# i3c_reva register map
Registers are 32-bit, read-write, no defined reset value unless marked. A register's access mark holds for its fields unless they carry their own. Offsets are from the block's base; lines under a group give offsets from that group; [hi:lo] are bit positions; {n}, {i} and the like mark numbered series; 'fields as' and 'values as' point back to an identical list; <NAME> marks a mode.

## Memory map
0x40018000 I3C0 size 0x1000 — Improved Inter-Integrated Circuit.

## Interrupts
30 I3C0 — I3C0 IRQ

## I3C0 — Improved Inter-Integrated Circuit.
Base 0x40018000
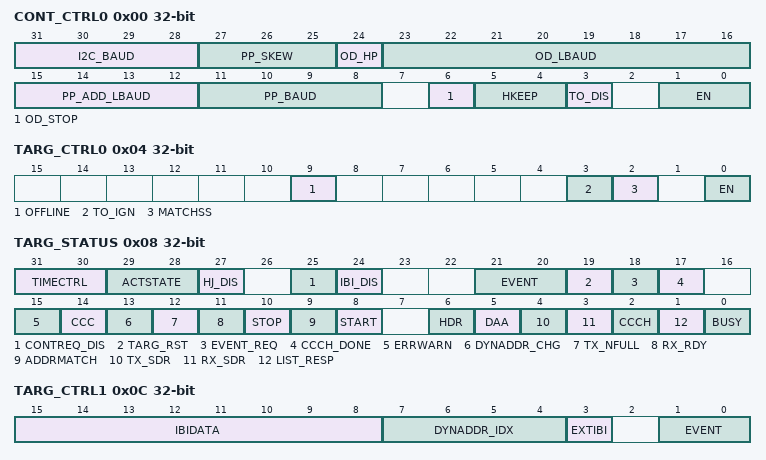
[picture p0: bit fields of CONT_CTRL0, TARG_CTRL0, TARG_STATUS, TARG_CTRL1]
0x00 CONT_CTRL0 — Controller Control 0 (Configuration) Register.
  [31:28] I2C_BAUD — Detyermines SCL high and low pweriods for I2C mode, in units of OD_BAUD period.
  [27:25] PP_SKEW — Number of FCLK periods to delay the SDA value change from the SCL edge for I3C push-pull operation.
  [24] OD_HP — Controls SCL high period for I3C oepn-drain operation.
  [23:16] OD_LBAUD — Number of PP_BAUD periods minus 1 to make one SCL low period for I3C open-dran periods.
  [15:12] PP_ADD_LBAUD — Number of FCLK periods to add to the base of SCL low period.
    0=0_FCLK (Adds zero FCLK periods to the SCL low period.); 1=1_FCLK (Adds one FCLK period to the SCL low period.); 2=2_FCLK (Adds two FCLK periods to the SCL low period.); 3=3_FCLK (Adds three FCLK periods to the SCL low period.); 4=4_FCLK (Adds four FCLK periods to the SCL low period.); 5=5_FCLK (Adds five FCLK periods to the SCL low period.); 6=6_FCLK (Adds six FCLK periods to the SCL low period.); 7=7_FCLK (Adds seven FCLK periods to the SCL low period.); 8=8_FCLK (Adds eight FCLK periods to the SCL low period.); 9=9_FCLK (Adds nine FCLK periods to the SCL low period.); 10=10_FCLK (Adds ten FCLK periods to the SCL low period.); 11=11_FCLK (Adds eleven FCLK periods to the SCL low period.); 12=12_FCLK (Adds twelve FCLK periods to the SCL low period.); 13=13_FCLK (Adds thirteen FCLK periods to the SCL low period.); 14=14_FCLK (Adds fourteen FCLK periods to the SCL low period.); 15=15_FCLK (Adds fifthteen FCLK periods to the SCL low period.)
  [11:8] PP_BAUD — SCL Frequency for push-pull drive.
    0=1_FCLK (SCL High Period is one FCLK Period.); 1=2_FCLK (SCL High Period is two FLCK Periods.); 2=3_FCLK (SCL High Period is three FCLK Period.); 3=4_FCLK (SCL High Period is four FCLK Period.); 4=5_FCLK (SCL High Period is five FCLK Period.); 5=6_FCLK (SCL High Period is six FCLK Period.); 6=7_FCLK (SCL High Period is seven FCLK Period.); 7=8_FCLK (SCL High Period is eight FCLK Period.); 8=9_FCLK (SCL High Period is nine FCLK Period.); 9=10_FCLK (SCL High Period is ten FCLK Period.); 10=11_FCLK (SCL High Period is eleven FCLK Period.); 11=12_FCLK (SCL High Period is twelve FCLK Period.); 12=13_FCLK (SCL High Period is thirteen FCLK Period.); 13=14_FCLK (SCL High Period is fourteen FCLK Period.); 14=15_FCLK (SCL High Period is fifthteen FCLK Period.); 15=16_FCLK (SCL High Period is sixteen FCLK Period.)
  [6] OD_STOP — Use open-drain speed for STOP.
  [5:4] HKEEP — High-keepr implementation.
    0=OFF (No high-keeper support.); 1=ON_CHIP (On-chip high-keeper support.); 2=EXT_SDA (External high-keeper support for SDA.); 3=EXT_SCL_SDA (External high-keeper support for SCL and SDA.)
  [3] TO_DIS — Disable Timeout error.
  [1:0] EN — I3C Device Enable.
    0=OFF; 1=ON; 2=CAP (I23 Bug Target with secondary controller capability.)
0x04 TARG_CTRL0 — Target Control 0 (Configuration) Register.
  [9] OFFLINE — Rejoin I3C bus with existing dynamic address.
  [3] TO_IGN — Ignore Timeout Errors.
  [2] MATCHSS — Match STOP and START.
  [0] EN — Target device enable.
0x08 TARG_STATUS access not given — Target Status Register.
  [31:30] TIMECTRL ro — Time Control mode.
    0=DIS (No timing control mode is enabled.); 1=SYNC (Synchronous Mode is enabled.); 2=ASYNC (Asynchronous Mode is enabled.); 3=BOTH (Both synchronous and asynchronous modes are enabled.)
  [29:28] ACTSTATE ro — Holds the current activity state.
    0=NORMAL (No latency, normal bus operation.); 1=1MS_LAT (1 ms latency.); 2=100MS_LAT (100 ms latency.); 3=10S_LAT (10 s latency.)
  [27] HJ_DIS ro — Indicates whether Hot-Joinevents are disabled.
  [25] CONTREQ_DIS ro — Indicates whether bus controller request events are disabled.
  [24] IBI_DIS ro — Indicates whether IBI events are disabled.
  [21:20] EVENT ro — Event Status.
    0=NONE (No event.); 1=REQ_PEND (Request not yet sent.); 2=REQ_NACK (Request was sent and NACKed and will be tried again.); 3=REQ_ACK (Request was sent and ACKed.)
  [19] TARG_RST rw — Target Reset.
  [18] EVENT_REQ rw — Event Requested.
  [17] CCCH_DONE rw — CCC Handled.
  [15] ERRWARN ro — An error or warning has occurred.
  [14] CCC rw — CCC received.
  [13] DYNADDR_CHG rw — Dynamic address changed.
  [12] TX_NFULL rw — TX FIFO is not full, ready to accept more data.
  [11] RX_RDY ro — Receive data ready.
  [10] STOP rw — STOP Detected.
  [9] ADDRMATCH rw — Address Matched.
  [8] START rw — START Detected.
  [6] HDR ro — HDR Mode.
  [5] DAA ro — Dynamic Address Assignment Mode.
  [4] TX_SDR — SDR Write.
  [3] RX_SDR — SDR Read.
  [2] CCCH ro — CCC is being handled.
  [1] LIST_RESP ro — Message status - listening/responding or not.
  [0] BUSY ro — Not stopped.
0x0C TARG_CTRL1 — Target Control 1 Register.
  [15:8] IBIDATA — Contains the mandatory data byte to be sent when generating an IBI.
  [7:4] DYNADDR_IDX — Index of dynamic address for the current IBI request.
  [3] EXTIBI — Indicates there are extended IBI data bytes.
  [1:0] EVENT — Sets respecive I3C target event request.
    0=NORMAL (Normal mode.); 1=IBI (Generate an IBI on the I3C bus.); 2=CONTREQ (Request control of the I3C bus.); 3=HJ (Generate a Hot-Join request.)
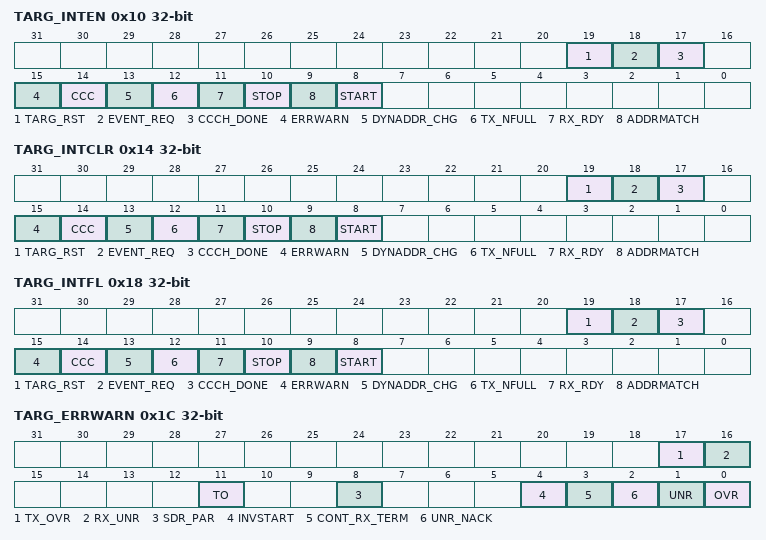
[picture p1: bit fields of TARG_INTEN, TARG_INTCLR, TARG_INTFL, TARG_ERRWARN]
0x10 TARG_INTEN — Target Interrupt Enable Register.
  [19] TARG_RST — I3C Target Reset Interrupt.
  [18] EVENT_REQ — Event Reqeusted Interrupt.
  [17] CCCH_DONE — CCC Handled Interrupt.
  [15] ERRWARN — Error or warning interrupt.
  [14] CCC — CCC Reveived Interrupt.
  [13] DYNADDR_CHG — Dynamic Address Changed interrupt enable.
  [12] TX_NFULL — Ready for transmit data,
  [11] RX_RDY — Receive data ready.
  [10] STOP — STOP detected.
  [9] ADDRMATCH — Address matched interrupt.
  [8] START — START detected.
0x14 TARG_INTCLR wo — Target Interrupt Clear Register.
  fields as TARG_INTEN
0x18 TARG_INTFL ro — Target Interrupt Flag Register.
  fields as TARG_INTEN
0x1C TARG_ERRWARN — Target Error and Warning Register.
  [17] TX_OVR — Write data overrun.
  [16] RX_UNR — Read data underrun.
  [11] TO — Timeout Error.
  [8] SDR_PAR — SDR Parity Error.
  [4] INVSTART — Invalid START.
  [3] CONT_RX_TERM — Controller terminated read in message mode.
  [2] UNR_NACK — I3C or I2C mode address emitted by the IP was NACKed by the targets.
  [1] UNR — Internal FIFO underrun flag.
  [0] OVR — Internal FIFO overrun flag.
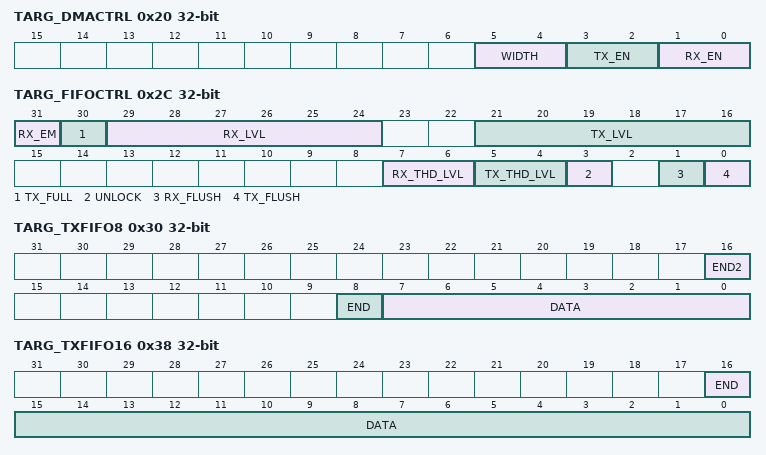
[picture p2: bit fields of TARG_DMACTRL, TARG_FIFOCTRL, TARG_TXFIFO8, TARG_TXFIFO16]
0x20 TARG_DMACTRL — Target DMA Control Register.
  [5:4] WIDTH — Selects the data width for DMA transfers.
    0=BYTE (Byte size.); 2=HALFWORD (Halfword size.)
  [3:2] TX_EN — DMA write enable.
    0=DIS (Disable DMA.); 1=ONE_FR (Enable DMA for one frame.); 2=EN (Enable DMA until disabled by setting this field to 0b00.)
  [1:0] RX_EN — DMA read enable.
    values as TX_EN
0x2C TARG_FIFOCTRL access per field — Target FIFO Control Register.
  [31] RX_EM ro — RX FIFO Empty Flag.
  [30] TX_FULL ro — TX FIFO Full flag.
  [29:24] RX_LVL ro — Number of messages in RX FIFO.
  [21:16] TX_LVL ro — Number of messages in TX FIFO.
  [7:6] RX_THD_LVL rw — RX FIFO trigger level.
    0=NOT_EMPTY (Trigger when empty.); 1=QUARTER_FULL (Trigger when quarter full or less.); 2=HALF_FULL (Trigger when half full or less.); 3=3_QUARTER_FULL (Trigger when 3 quarters full or less.)
  [5:4] TX_THD_LVL rw — TX FIFO trigger level.
    0=EMPTY (Trigger when empty.); 1=QUARTER_FULL (Trigger when quarter full or less.); 2=HALF_FULL (Trigger when half full or less.); 3=ALMOST_FULL (Trigger when almost full or less.)
  [3] UNLOCK wo — Unlock FIFO Triggers.
  [1] RX_FLUSH wo — Flush RX FIFO.
  [0] TX_FLUSH wo — Flush TX FIFO.
0x30 TARG_TXFIFO8 wo — Target Write Byte Data Register.
  [16] END2 — End of data.
  [8] END — End of data.
  [7:0] DATA — Data byte to send.
0x34 TARG_TXFIFO8E wo — Target Write Byte Data as End Register.
  [7:0] DATA — Data is read from or written to this location. Transmit and receive FIFO are separate but both are addressed at this location.
0x38 TARG_TXFIFO16 wo — Target Write Half-Word Data Register.
  [16] END — End of data.
  [15:0] DATA — Data halfword to send.
0x3C TARG_TXFIFO16E wo — Target Write Half-Word Data as End Register.
  [15:0] DATA — Data halfword to send.
0x40 TARG_RXFIFO8 ro — Target Read Byte Data Register.
  [7:0] DATA — Read data byte from RX FIFO.
0x48 TARG_RXFIFO16 ro — Target Read Half-Word Data Register.
  [15:0] DATA — Read data hyalfword from RX FIFO.
0x54 TARG_TXFIFO8O wo — Target Byte-Only Write Byte Data Register.
  [7:0] DATA — Data byte to send.
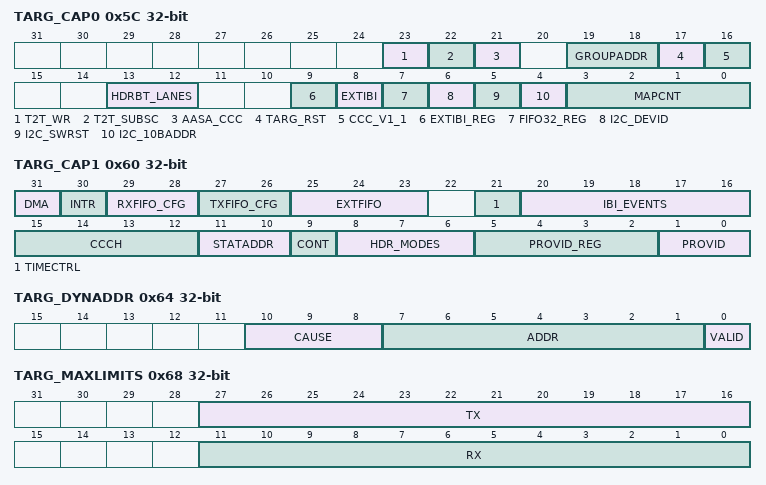
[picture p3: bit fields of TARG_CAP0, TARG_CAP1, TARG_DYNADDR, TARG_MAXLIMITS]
0x5C TARG_CAP0 ro — Target Capabilities 0 Register.
  [23] T2T_WR — Target-to-target write support.
  [22] T2T_SUBSC — Target-to-target subscriber support.
  [21] AASA_CCC — SETAASA CCC Support.
  [19:18] GROUPADDR — Group address support.
  [17] TARG_RST — Target Reset Support.
  [16] CCC_V1_1 — CCC V1.1 Support.
  [13:12] HDRBT_LANES — Multi-lane support for HDR-BT mode.
  [9] EXTIBI_REG — Extended IBI data register support.
  [8] EXTIBI — Extended IBI data support.
  [7] FIFO32_REG — FIFO 32 registers available.
  [6] I2C_DEVID — I2C Device ID Support.
  [5] I2C_SWRST — I2C Software Reset Support.
  [4] I2C_10BADDR — I2C 10-bit address support.
  [3:0] MAPCNT — Number of mapped target addresses supported.
0x60 TARG_CAP1 ro — TARG_Capabilities 1 Register.
  [31] DMA — DMA support.
  [30] INTR — Interrupt support.
  [29:28] RXFIFO_CFG — RX FIFO configuration.
  [27:26] TXFIFO_CFG — TX FIFO configuration.
  [25:23] EXTFIFO — External FIFO configuration.
  [21] TIMECTRL — Timing Control Support.
  [20:16] IBI_EVENTS — Supported IBI events.
    1=IBI (IBI support.); 2=PAYLOAD (IBI has payload.); 4=CONTREQ (Controller request support.); 8=HJ (Hot-Join support.); 16=BAMATCH (Use BAMATCH field of CONFIG register to measure 1us Bus Available timing.)
  [15:12] CCCH — CCC Handled by IP.
    1=BASIC (Basic CCCs.); 2=LIMITS (CCCs related to maximum transfer lengths and speed.); 4=INTACT (Pending Interrupt and Activity Mode fields of GETSTATUS CCC.); 8=VENDOR (Vendor Reserved field of GETSTATUS CCC.)
  [11:10] STATADDR — I2C-style static address implementation.
  [9] CONT — Controller mode capable.
  [8:6] HDR_MODES — Supported HDR modes.
  [5:2] PROVID_REG — Provision ID, Bus Characteristics, Device Characteristics implementation.
  [1:0] PROVID — Provisioned ID implementation.
0x64 TARG_DYNADDR — Target Dynamic Address Register.
  [10:8] CAUSE — Indicates how the last primary dynnamic address value change occurred.
  [7:1] ADDR — The assigned dynamic address.
  [0] VALID — Address valid check.
0x68 TARG_MAXLIMITS — Maximum Limits Register.
  [27:16] TX — The maximum number of bytes that the I3C controller may write from this I3C target device per message.
  [11:0] RX — The maximum number of bytes that the I3C controller may read from this I3C target device per message.
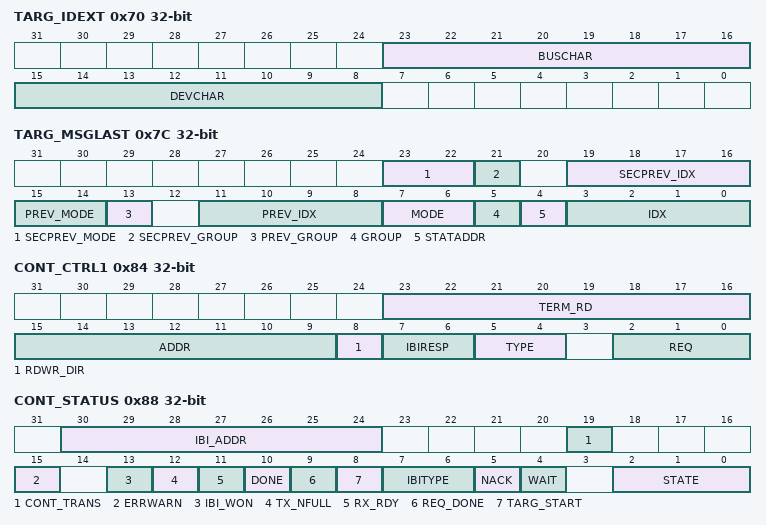
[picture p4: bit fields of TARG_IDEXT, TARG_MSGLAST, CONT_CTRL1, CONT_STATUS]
0x70 TARG_IDEXT — ID Extension Register.
  [23:16] BUSCHAR — Bus Characteristics Register.
  [15:8] DEVCHAR — Device Characteristics Register.
0x7C TARG_MSGLAST ro — Target Matching Address Index Register.
  [23:22] SECPREV_MODE — Indicates the mode of the secondary previous access.
    0=DYN_STAT_ADDR (I3C SDR or I2C); 1=HDR_DDR; 2=HDR_BT
  [21] SECPREV_GROUP — Last matched address was a secondary previous group address.
  [19:16] SECPREV_IDX — Index or group number of secondary previous matched address.
  [15:14] PREV_MODE — Indicates the mode of the previous access.
    0=DYN_STAT_ADDR (I3C SDR or I2C); 1=HDR_DDR; 2=HDR_BT
  [13] PREV_GROUP — Last matched address was a previous group address.
  [11:8] PREV_IDX — Index or group number of previous matched address.
  [7:6] MODE — Indicates the mode of the last access.
    0=DYN_STAT_ADDR (I3C SDR or I2C); 1=HDR_DDR; 2=HDR_BT
  [5] GROUP — Last matched address was a group address.
  [4] STATADDR — Last matched address was a I2C static address.
  [3:0] IDX — Index or group number of last matched address.
0x84 CONT_CTRL1 — Controller Control 1 Register.
  [23:16] TERM_RD — Termination count for read.
  [15:9] ADDR — Address to send with START.
  [8] RDWR_DIR — Direction of the transfer.
  [7:6] IBIRESP — Response to use when an IBI occurs.
  [5:4] TYPE — Controls type of operation for REQ field.
  [2:0] REQ — Requests an I3C or I2C bus operation.
    0=NONE (None operation.); 1=EMIT_START (Emit a START with address and read-write bit from stopped state or in the middle of an SDR message.); 2=EMIT_STOP (Emit a STOP.); 3=IBI_ACKNACK (Manually ACK or NACK an IBI.); 4=PROCESS_DAA (Process Dynamic Address Assignment.); 6=EXIT_RST (Emit HDR Exit Pattern or Target Reset pattern.); 7=AUTO_IBI (Automatic IBI response.)
0x88 CONT_STATUS access not given — Controller Status Register.
  [30:24] IBI_ADDR ro — The address of a received IBI or dcontroller request.
  [19] CONT_TRANS rw — IP transitioned from I3C target to controller.
  [15] ERRWARN ro — Error or warning status.
  [13] IBI_WON rw — IBI Arbitration won.
  [12] TX_NFULL ro — TX FIFO Not Full flag.
  [11] RX_RDY ro — Receive data ready.
  [10] DONE rw — Message completed.
  [9] REQ_DONE ro — CTRL1 Request completed.
  [8] TARG_START — Target START detected.
  [7:6] IBITYPE — The type of event for which arbitration was last won.
    0=NONE; 1=IBI (In-band Interrupt.); 2=CONT_REQ (Controller request.); 3=HOTJOIN_REQ (Hot-Join request.)
  [5] NACK ro — Address was NACKed.
  [4] WAIT ro — Depending on STATE, WAIT is 1 when it's waiting in an intermediary state.
  [2:0] STATE ro — Current working state.
    0=IDLE (Bus Idle.); 1=TARG_REQ (I3C Bus i stopped and a target is holding SDA low.); 2=SDR_TXSDRMSG (SDR Message Mode using SDRMSG registers.); 3=SDR_NORM (Normal SDR message mode.); 4=DDR (DDR Message mode); 5=DAA (Dynamic Address Assignment mode.); 6=IBI_ACKNACK (IP is waiting for the application to provide an ACK or NACK decision.); 7=IBI_RX (IP is receiving an IBI.)
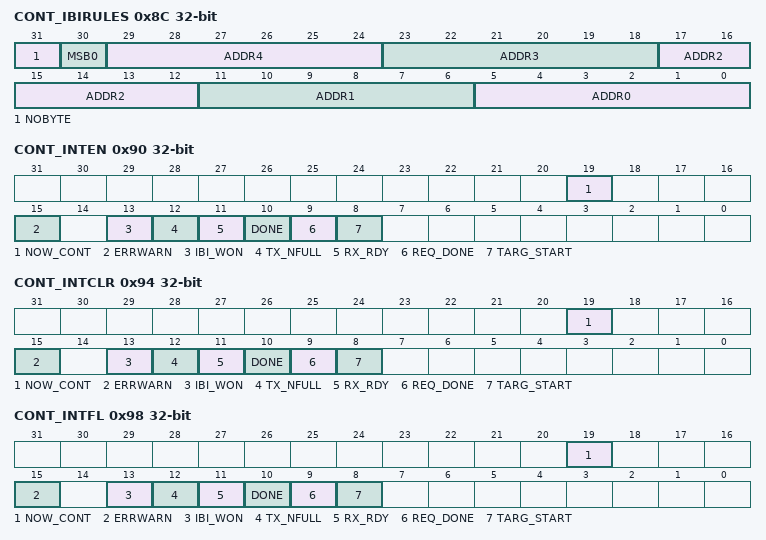
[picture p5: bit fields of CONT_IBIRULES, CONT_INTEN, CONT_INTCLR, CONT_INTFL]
0x8C CONT_IBIRULES — Controller IBI Registry and Rules Register.
  [31] NOBYTE — Specifies the function of ADDR0 to ADDR4
  [30] MSB0 — Implementation of MSb for I3C dynamic addresses.
  [6n+5:6n] ADDR{n} (n=0..4) — Target {n} dynamic address.
0x90 CONT_INTEN — Controller Interrupt Enable Register.
  [19] NOW_CONT — The IP transitioned from I3C bus target to I3C bus controller.
  [15] ERRWARN — Error or warning interrupt.
  [13] IBI_WON — IBI arbitration won.
  [12] TX_NFULL — Ready for transmit data,
  [11] RX_RDY — Receive data ready.
  [10] DONE — Message complete.
  [9] REQ_DONE — CTRL request completed.
  [8] TARG_START — Target Start Detected.
0x94 CONT_INTCLR wo — Controller Interrupt Clear Register.
  fields as CONT_INTEN
0x98 CONT_INTFL ro — Controller Interrupt Flag Register.
  fields as CONT_INTEN
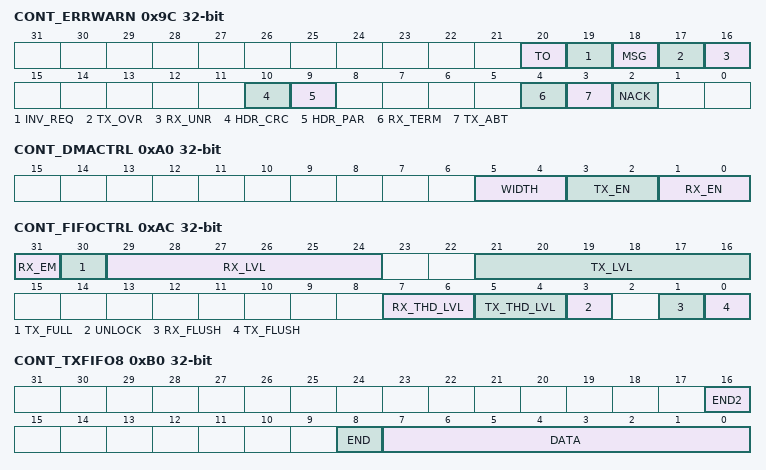
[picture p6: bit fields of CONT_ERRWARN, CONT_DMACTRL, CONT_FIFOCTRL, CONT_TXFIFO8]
0x9C CONT_ERRWARN — Controller Error and Warning Register.
  [20] TO — Timeout error.
  [19] INV_REQ — Invalid use of request from CTRL register.
  [18] MSG — Message mode error.
  [17] TX_OVR — Write data overrun.
  [16] RX_UNR — Read data underrun.
  [10] HDR_CRC — HDR-DDR CRC Error.
  [9] HDR_PAR — HDR Parity Error.
  [4] RX_TERM — Controller terminated read in messaage mode.
  [3] TX_ABT — Write aborted due to data NACK.
  [2] NACK — I3C or I2C mode address emitted by the IP was NACKed by the targets.
0xA0 CONT_DMACTRL — Controller DMA Control Register.
  fields as TARG_DMACTRL
0xAC CONT_FIFOCTRL access per field — Controller FIFO Control Register.
  fields as TARG_FIFOCTRL
0xB0 CONT_TXFIFO8 wo — Controller Write Byte Data Register.
  fields as TARG_TXFIFO8
0xB4 CONT_TXFIFO8E wo — Controller Write Byte Data as End Register.
  fields as TARG_TXFIFO8E
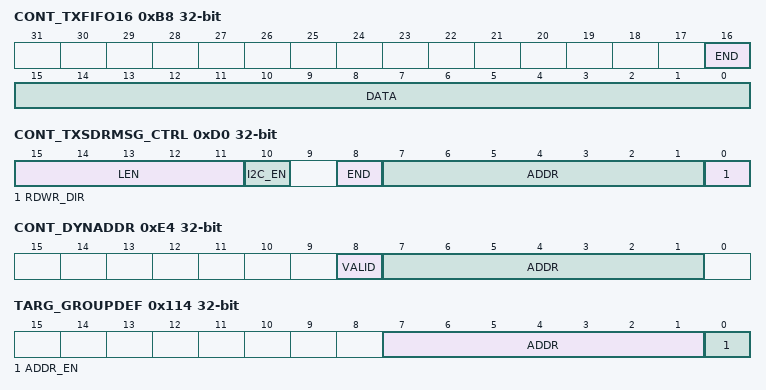
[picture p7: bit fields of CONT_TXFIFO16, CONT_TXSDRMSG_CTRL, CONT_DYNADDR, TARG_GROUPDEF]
0xB8 CONT_TXFIFO16 wo — Controller Write Half-Word Data Register.
  [16] END — End of data.
  [15:0] DATA — Data halfword to send.
0xBC CONT_TXFIFO16E wo — Controller Write Half-Word Data as End Register.
  [15:0] DATA — Data halfword to send.
0xC0 CONT_RXFIFO8 ro — Controller Read Byte Data Register.
  [7:0] DATA — Read data byte from RX FIFO.
0xC8 CONT_RXFIFO16 ro — Controller Read Half-Word Data Register.
  [15:0] DATA — Read data hyalfword from RX FIFO.
0xCC CONT_TXFIFO8O wo — Controller Byte-Only Write Byte Data Register.
  [7:0] DATA — Data byte to send.
0xD0 CONT_TXSDRMSG_CTRL — Controller Start or Continue SDR Message Register.
  [15:11] LEN — Message length in bytes.
  [10] I2C_EN — I2C Mode Enable.
  [8] END — Select how to end message.
  [7:1] ADDR — Destination address of message.
  [0] RDWR_DIR — Direction of the transfer.
0xD0 CONT_TXSDRMSG_FIFO wo — Controller Start or Continue SDR Message Register.
  [15:0] DATA — Data for SDR write message after control information has been written.
0xD4 CONT_RXSDRMSG ro — Controller Read SDR Message Data Register.
  fields as CONT_TXSDRMSG_FIFO
0xD8 CONT_TXDDRMSG wo — Controller Start or Continue DDR Message Register.
  [15:0] MSG — Data, address/command, and control information.
0xDC CONT_RXDDR16 ro — Controller Read DDR Message Data Register.
  [15:0] DATA — Read data (16bits).
0xE4 CONT_DYNADDR — Controller Dynamic Address Register.
  [8] VALID — Address valid check.
  [7:1] ADDR — The assigned dynamic address.
0x114 TARG_GROUPDEF ro — Target Group Definition Register.
  [7:1] ADDR — Group Address .
  [0] ADDR_EN — Group Address enable.
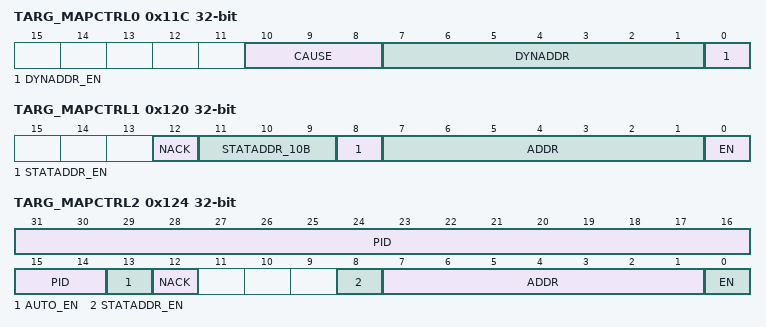
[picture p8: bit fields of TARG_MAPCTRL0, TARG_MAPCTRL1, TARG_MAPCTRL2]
0x11C TARG_MAPCTRL0 — Target Primary Map Control Register.
  [10:8] CAUSE — Indicates how the last primary dynamic address value change occurred.
  [7:1] DYNADDR — Dynamic address.
  [0] DYNADDR_EN — Dynamic address is enabled.
0x120 TARG_MAPCTRL1 — Target Map Control 1 Register.
  [12] NACK — Indicates how the last primary dynamic address value change occurred.
  [11:9] STATADDR_10B — Contains the upper 3 bits of a 10-bit I2C Static Address.
  [8] STATADDR_EN — ADDR field contains the I2C static address if enabled.
  [7:1] ADDR — Static or Dynamic address.
  [0] EN — Mapped address slot is enabled.
0x124 TARG_MAPCTRL2 — Target Map Control 2 Register.
  [31:14] PID — Indicates how the last primary dynamic address value change occurred.
  [13] AUTO_EN — Enable slot for automatic dynamic address assignment.
  [12] NACK — Indicates how the last primary dynamic address value change occurred.
  [8] STATADDR_EN — ADDR field contains the I2C static address if enabled.
  [7:1] ADDR — Static or Dynamic address.
  [0] EN — Mapped address slot is enabled.
